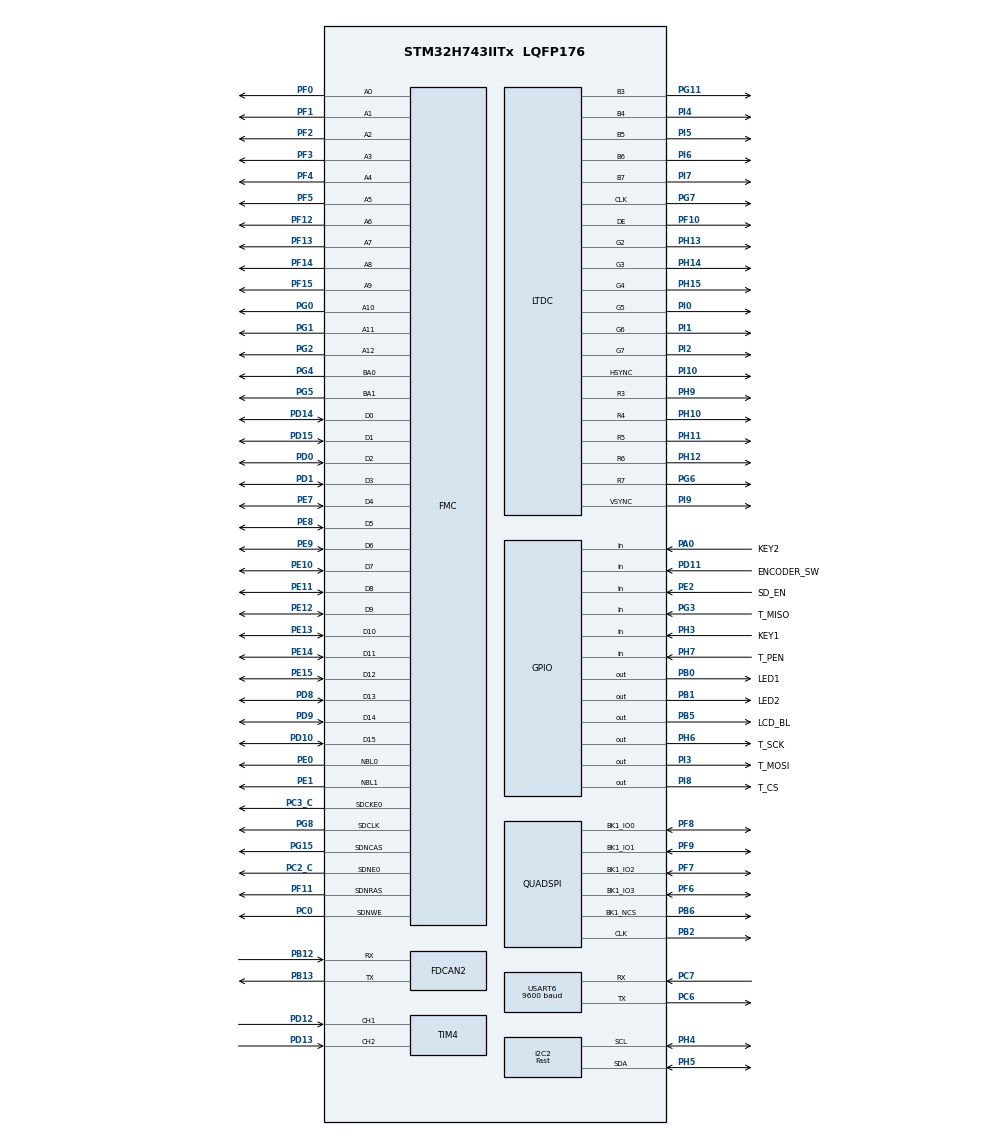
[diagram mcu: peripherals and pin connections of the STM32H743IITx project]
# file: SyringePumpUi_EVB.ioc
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CORTEX_M7.AccessPermission-Cortex_Memory_Protection_Unit_Region1_Settings=MPU_REGION_FULL_ACCESS
CORTEX_M7.AccessPermission-Cortex_Memory_Protection_Unit_Region2_Settings=MPU_REGION_FULL_ACCESS
CORTEX_M7.AccessPermission-Cortex_Memory_Protection_Unit_Region3_Settings=MPU_REGION_FULL_ACCESS
CORTEX_M7.AccessPermission-Cortex_Memory_Protection_Unit_Region4_Settings=MPU_REGION_FULL_ACCESS
CORTEX_M7.AccessPermission-Cortex_Memory_Protection_Unit_Region5_Settings=MPU_REGION_FULL_ACCESS
CORTEX_M7.AccessPermission-Cortex_Memory_Protection_Unit_Region6_Settings=MPU_REGION_FULL_ACCESS
CORTEX_M7.AccessPermission-Cortex_Memory_Protection_Unit_Region7_Settings=MPU_REGION_FULL_ACCESS
CORTEX_M7.BaseAddress-Cortex_Memory_Protection_Unit_Region1_Settings=0x90000000
CORTEX_M7.BaseAddress-Cortex_Memory_Protection_Unit_Region2_Settings=0xC0000000
CORTEX_M7.BaseAddress-Cortex_Memory_Protection_Unit_Region3_Settings=0x20000000
CORTEX_M7.BaseAddress-Cortex_Memory_Protection_Unit_Region4_Settings=0x24000000
CORTEX_M7.BaseAddress-Cortex_Memory_Protection_Unit_Region5_Settings=0x30000000
CORTEX_M7.BaseAddress-Cortex_Memory_Protection_Unit_Region6_Settings=0x38000000
CORTEX_M7.BaseAddress-Cortex_Memory_Protection_Unit_Region7_Settings=0x60000000
CORTEX_M7.CPU_DCache=Enabled
CORTEX_M7.CPU_ICache=Enabled
CORTEX_M7.DisableExec-Cortex_Memory_Protection_Unit_Region0_Settings=MPU_INSTRUCTION_ACCESS_DISABLE
CORTEX_M7.DisableExec-Cortex_Memory_Protection_Unit_Region2_Settings=MPU_INSTRUCTION_ACCESS_ENABLE
CORTEX_M7.Enable-Cortex_Memory_Protection_Unit_Region0_Settings=MPU_REGION_ENABLE
CORTEX_M7.Enable-Cortex_Memory_Protection_Unit_Region1_Settings=MPU_REGION_ENABLE
CORTEX_M7.Enable-Cortex_Memory_Protection_Unit_Region2_Settings=MPU_REGION_ENABLE
CORTEX_M7.Enable-Cortex_Memory_Protection_Unit_Region3_Settings=MPU_REGION_ENABLE
CORTEX_M7.Enable-Cortex_Memory_Protection_Unit_Region4_Settings=MPU_REGION_ENABLE
CORTEX_M7.Enable-Cortex_Memory_Protection_Unit_Region5_Settings=MPU_REGION_ENABLE
CORTEX_M7.Enable-Cortex_Memory_Protection_Unit_Region6_Settings=MPU_REGION_ENABLE
CORTEX_M7.Enable-Cortex_Memory_Protection_Unit_Region7_Settings=MPU_REGION_ENABLE
CORTEX_M7.Enable-Cortex_Memory_Protection_Unit_Region8_Settings=__NULL
CORTEX_M7.IsBufferable-Cortex_Memory_Protection_Unit_Region2_Settings=MPU_ACCESS_BUFFERABLE
CORTEX_M7.IsBufferable-Cortex_Memory_Protection_Unit_Region3_Settings=MPU_ACCESS_BUFFERABLE
CORTEX_M7.IsBufferable-Cortex_Memory_Protection_Unit_Region4_Settings=MPU_ACCESS_BUFFERABLE
CORTEX_M7.IsBufferable-Cortex_Memory_Protection_Unit_Region5_Settings=MPU_ACCESS_BUFFERABLE
CORTEX_M7.IsBufferable-Cortex_Memory_Protection_Unit_Region6_Settings=MPU_ACCESS_BUFFERABLE
CORTEX_M7.IsCacheable-Cortex_Memory_Protection_Unit_Region1_Settings=MPU_ACCESS_CACHEABLE
CORTEX_M7.IsCacheable-Cortex_Memory_Protection_Unit_Region2_Settings=MPU_ACCESS_CACHEABLE
CORTEX_M7.IsCacheable-Cortex_Memory_Protection_Unit_Region3_Settings=MPU_ACCESS_CACHEABLE
CORTEX_M7.IsCacheable-Cortex_Memory_Protection_Unit_Region4_Settings=MPU_ACCESS_CACHEABLE
CORTEX_M7.IsCacheable-Cortex_Memory_Protection_Unit_Region5_Settings=MPU_ACCESS_CACHEABLE
CORTEX_M7.IsCacheable-Cortex_Memory_Protection_Unit_Region6_Settings=MPU_ACCESS_CACHEABLE
CORTEX_M7.IsShareable-Cortex_Memory_Protection_Unit_Region0_Settings=MPU_ACCESS_SHAREABLE
CORTEX_M7.MPU_Control=__NULL
CORTEX_M7.Size-Cortex_Memory_Protection_Unit_Region0_Settings=MPU_REGION_SIZE_4GB
CORTEX_M7.Size-Cortex_Memory_Protection_Unit_Region1_Settings=MPU_REGION_SIZE_32MB
CORTEX_M7.Size-Cortex_Memory_Protection_Unit_Region2_Settings=MPU_REGION_SIZE_32MB
CORTEX_M7.Size-Cortex_Memory_Protection_Unit_Region3_Settings=MPU_REGION_SIZE_128KB
CORTEX_M7.Size-Cortex_Memory_Protection_Unit_Region4_Settings=MPU_REGION_SIZE_512KB
CORTEX_M7.Size-Cortex_Memory_Protection_Unit_Region5_Settings=MPU_REGION_SIZE_512KB
CORTEX_M7.Size-Cortex_Memory_Protection_Unit_Region6_Settings=MPU_REGION_SIZE_64KB
CORTEX_M7.Size-Cortex_Memory_Protection_Unit_Region7_Settings=MPU_REGION_SIZE_64KB
CORTEX_M7.SubRegionDisable-Cortex_Memory_Protection_Unit_Region0_Settings=0x87
DMA2D.ColorMode=DMA2D_OUTPUT_RGB565
Dma.I2C2_RX.0.Direction=DMA_PERIPH_TO_MEMORY
Dma.I2C2_RX.0.EventEnable=DISABLE
Dma.I2C2_RX.0.FIFOMode=DMA_FIFOMODE_DISABLE
Dma.I2C2_RX.0.Instance=DMA1_Stream0
Dma.I2C2_RX.0.MemDataAlignment=DMA_MDATAALIGN_BYTE
Dma.I2C2_RX.0.MemInc=DMA_MINC_ENABLE
Dma.I2C2_RX.0.Mode=DMA_NORMAL
Dma.I2C2_RX.0.PeriphDataAlignment=DMA_PDATAALIGN_BYTE
Dma.I2C2_RX.0.PeriphInc=DMA_PINC_DISABLE
Dma.I2C2_RX.0.Polarity=HAL_DMAMUX_REQ_GEN_RISING
Dma.I2C2_RX.0.Priority=DMA_PRIORITY_LOW
Dma.I2C2_RX.0.RequestNumber=1
Dma.I2C2_RX.0.SignalID=NONE
Dma.I2C2_RX.0.SyncEnable=DISABLE
Dma.I2C2_RX.0.SyncPolarity=HAL_DMAMUX_SYNC_NO_EVENT
Dma.I2C2_RX.0.SyncRequestNumber=1
Dma.I2C2_RX.0.SyncSignalID=NONE
Dma.I2C2_TX.1.Direction=DMA_MEMORY_TO_PERIPH
Dma.I2C2_TX.1.EventEnable=DISABLE
Dma.I2C2_TX.1.FIFOMode=DMA_FIFOMODE_DISABLE
Dma.I2C2_TX.1.Instance=DMA1_Stream1
Dma.I2C2_TX.1.MemDataAlignment=DMA_MDATAALIGN_BYTE
Dma.I2C2_TX.1.MemInc=DMA_MINC_ENABLE
Dma.I2C2_TX.1.Mode=DMA_NORMAL
Dma.I2C2_TX.1.PeriphDataAlignment=DMA_PDATAALIGN_BYTE
Dma.I2C2_TX.1.PeriphInc=DMA_PINC_DISABLE
Dma.I2C2_TX.1.Polarity=HAL_DMAMUX_REQ_GEN_RISING
Dma.I2C2_TX.1.Priority=DMA_PRIORITY_LOW
Dma.I2C2_TX.1.RequestNumber=1
Dma.I2C2_TX.1.SignalID=NONE
Dma.I2C2_TX.1.SyncEnable=DISABLE
Dma.I2C2_TX.1.SyncPolarity=HAL_DMAMUX_SYNC_NO_EVENT
Dma.I2C2_TX.1.SyncRequestNumber=1
Dma.I2C2_TX.1.SyncSignalID=NONE
Dma.Request0=I2C2_RX
Dma.Request1=I2C2_TX
FDCAN2.CalculateBaudRateNominal=1250000
FDCAN2.CalculateTimeBitNominal=800
FDCAN2.CalculateTimeQuantumNominal=160.0
FMC.CASLatency1=FMC_SDRAM_CAS_LATENCY_3
FMC.ColumnBitsNumber1=FMC_SDRAM_COLUMN_BITS_NUM_9
FMC.ExitSelfRefreshDelay1=8
FMC.LoadToActiveDelay1=2
FMC.RCDDelay1=2
FMC.RPDelay1=2
FMC.RPDelay2=2
FMC.ReadBurst1=FMC_SDRAM_RBURST_ENABLE
FMC.ReadBurst2=FMC_SDRAM_RBURST_ENABLE
FMC.ReadPipeDelay1=FMC_SDRAM_RPIPE_DELAY_0
FMC.RowCycleDelay1=7
FMC.RowCycleDelay2=7
FMC.SDClockPeriod1=FMC_SDRAM_CLOCK_PERIOD_2
FMC.SDClockPeriod2=FMC_SDRAM_CLOCK_PERIOD_2
FMC.SelfRefreshTime1=5
FMC.WriteRecoveryTime1=4
I2C2.CustomTiming=Disabled
I2C2.I2C_Fall_Time=300
I2C2.I2C_Rise_Time=300
I2C2.I2C_Speed_Mode=I2C_Fast
I2C2.Timing=0x10950C1E
LTDC.ActiveW=800
LTDC.Alpha_L0=255
LTDC.Alpha_L1=255
LTDC.DEPolarity=LTDC_DEPOLARITY_AH
LTDC.FBStartAdress_L0=0xc0000000
LTDC.Green_L0=0
LTDC.HBP=8
LTDC.HFP=8
LTDC.HSPolarity=LTDC_HSPOLARITY_AL
LTDC.HSync=1
LTDC.ImageHeight_L0=480
LTDC.ImageHeight_L1=480
LTDC.ImageWidth_L0=800
LTDC.Layers=0
LTDC.PCPolarity=LTDC_PCPOLARITY_IIPC
LTDC.PixelFormat_L0=LTDC_PIXEL_FORMAT_RGB565
LTDC.Red_L0=0
LTDC.VBP=8
LTDC.VFP=8
LTDC.VSPolarity=LTDC_VSPOLARITY_AL
LTDC.VSync=1
LTDC.WindowX0_L0=0
LTDC.WindowX1_L0=800
LTDC.WindowX1_L1=800
LTDC.WindowY0_L0=0
LTDC.WindowY1_L0=480
LTDC.WindowY1_L1=480
Mcu.Family=STM32H7
Mcu.Name=STM32H743IITx
Mcu.Package=LQFP176
NVIC.DMA1_Stream0_IRQn=true\:0\:0\:false\:false\:true\:false\:true\:true
NVIC.DMA1_Stream1_IRQn=true\:0\:0\:false\:false\:true\:false\:true\:true
NVIC.DMA2D_IRQn=true\:0\:0\:false\:false\:true\:true\:true\:true
NVIC.I2C2_ER_IRQn=true\:0\:0\:false\:false\:true\:true\:true\:true
NVIC.I2C2_EV_IRQn=true\:0\:0\:false\:false\:true\:true\:true\:true
NVIC.LTDC_ER_IRQn=true\:0\:0\:false\:false\:true\:true\:true\:true
NVIC.LTDC_IRQn=true\:0\:0\:false\:false\:true\:true\:true\:true
NVIC.PriorityGroup=NVIC_PRIORITYGROUP_4
NVIC.TIM4_IRQn=true\:0\:0\:false\:false\:true\:true\:true\:true
PA0.GPIO_Label=KEY2
PA0.GPIO_PuPd=GPIO_PULLUP
PA0.Signal=GPIO_Input
PA13\ (JTMS/SWDIO).Mode=Serial_Wire
PA13\ (JTMS/SWDIO).Signal=DEBUG_JTMS-SWDIO
PA14\ (JTCK/SWCLK).Mode=Serial_Wire
PA14\ (JTCK/SWCLK).Signal=DEBUG_JTCK-SWCLK
PB0.GPIO_Label=LED1
PB0.GPIO_Speed=GPIO_SPEED_FREQ_VERY_HIGH
PB0.PinState=GPIO_PIN_RESET
PB0.Signal=GPIO_Output
PB1.GPIO_Label=LED2
PB1.GPIO_Speed=GPIO_SPEED_FREQ_VERY_HIGH
PB1.Signal=GPIO_Output
PB12.GPIO_PuPd=GPIO_PULLUP
PB12.GPIO_Speed=GPIO_SPEED_FREQ_MEDIUM
PB12.Mode=FDCAN_Activate
PB12.Signal=FDCAN2_RX
PB13.Mode=FDCAN_Activate
PB13.Signal=FDCAN2_TX
PB2.GPIO_Speed=GPIO_SPEED_FREQ_VERY_HIGH
PB2.Mode=Single Bank 1
PB2.Signal=QUADSPI_CLK
PB5.GPIO_Label=LCD_BL
PB5.GPIO_Speed=GPIO_SPEED_FREQ_VERY_HIGH
PB5.PinState=GPIO_PIN_SET
PB5.Signal=GPIO_Output
PB6.GPIO_FM6=SYSCFG_PMCR_I2C_PB6_FMP
PB6.GPIO_Speed=GPIO_SPEED_FREQ_VERY_HIGH
PB6.Mode=Single Bank 1
PB6.Signal=QUADSPI_BK1_NCS
PC0.Signal=FMC_SDNWE
PC2_C.Mode=SdramChipSelect1_1
PC2_C.Signal=FMC_SDNE0
PC3_C.Mode=SdramChipSelect1_1
PC3_C.Signal=FMC_SDCKE0
PC6.Mode=Asynchronous
PC6.Signal=USART6_TX
PC7.Mode=Asynchronous
PC7.Signal=USART6_RX
PD0.Signal=FMC_D2_DA2
PD1.Signal=FMC_D3_DA3
PD10.Signal=FMC_D15_DA15
PD11.GPIO_Label=ENCODER_SW
PD11.GPIO_PuPd=GPIO_PULLUP
PD11.Signal=GPIO_Input
PD12.Signal=S_TIM4_CH1
PD13.Signal=S_TIM4_CH2
PD14.Signal=FMC_D0_DA0
PD15.Signal=FMC_D1_DA1
PD8.Signal=FMC_D13_DA13
PD9.Signal=FMC_D14_DA14
PE0.Signal=FMC_NBL0
PE1.Signal=FMC_NBL1
PE10.Signal=FMC_D7_DA7
PE11.Signal=FMC_D8_DA8
PE12.Signal=FMC_D9_DA9
PE13.Signal=FMC_D10_DA10
PE14.Signal=FMC_D11_DA11
PE15.Signal=FMC_D12_DA12
PE2.GPIO_Label=SD_EN
PE2.GPIO_PuPd=GPIO_PULLDOWN
PE2.Signal=GPIO_Input
PE7.Signal=FMC_D4_DA4
PE8.Signal=FMC_D5_DA5
PE9.Signal=FMC_D6_DA6
PF0.Signal=FMC_A0
PF1.Signal=FMC_A1
PF10.GPIO_Speed=GPIO_SPEED_FREQ_VERY_HIGH
PF10.Mode=RGB565
PF10.Signal=LTDC_DE
PF11.Signal=FMC_SDNRAS
PF12.Signal=FMC_A6
PF13.Signal=FMC_A7
PF14.Signal=FMC_A8
PF15.Signal=FMC_A9
PF2.Signal=FMC_A2
PF3.Signal=FMC_A3
PF4.Signal=FMC_A4
PF5.Signal=FMC_A5
PF6.GPIO_Speed=GPIO_SPEED_FREQ_VERY_HIGH
PF6.Mode=Single Bank 1
PF6.Signal=QUADSPI_BK1_IO3
PF7.GPIO_Speed=GPIO_SPEED_FREQ_VERY_HIGH
PF7.Mode=Single Bank 1
PF7.Signal=QUADSPI_BK1_IO2
PF8.GPIO_Speed=GPIO_SPEED_FREQ_VERY_HIGH
PF8.Mode=Single Bank 1
PF8.Signal=QUADSPI_BK1_IO0
PF9.GPIO_Speed=GPIO_SPEED_FREQ_VERY_HIGH
PF9.Mode=Single Bank 1
PF9.Signal=QUADSPI_BK1_IO1
PG0.Signal=FMC_A10
PG1.Signal=FMC_A11
PG11.GPIO_Speed=GPIO_SPEED_FREQ_VERY_HIGH
PG11.Mode=RGB565
PG11.Signal=LTDC_B3
PG15.Signal=FMC_SDNCAS
PG2.Signal=FMC_A12
PG3.GPIO_Label=T_MISO
PG3.GPIO_PuPd=GPIO_PULLUP
PG3.Signal=GPIO_Input
PG4.Signal=FMC_A14_BA0
PG5.Signal=FMC_A15_BA1
PG6.GPIO_Speed=GPIO_SPEED_FREQ_VERY_HIGH
PG6.Mode=RGB565
PG6.Signal=LTDC_R7
PG7.GPIO_Speed=GPIO_SPEED_FREQ_VERY_HIGH
PG7.Mode=RGB565
PG7.Signal=LTDC_CLK
PG8.Signal=FMC_SDCLK
PH0-OSC_IN\ (PH0).Mode=HSE-External-Oscillator
PH0-OSC_IN\ (PH0).Signal=RCC_OSC_IN
PH1-OSC_OUT\ (PH1).Mode=HSE-External-Oscillator
PH1-OSC_OUT\ (PH1).Signal=RCC_OSC_OUT
PH10.GPIO_Speed=GPIO_SPEED_FREQ_VERY_HIGH
PH10.Mode=RGB565
PH10.Signal=LTDC_R4
PH11.GPIO_Speed=GPIO_SPEED_FREQ_VERY_HIGH
PH11.Mode=RGB565
PH11.Signal=LTDC_R5
PH12.GPIO_Speed=GPIO_SPEED_FREQ_VERY_HIGH
PH12.Mode=RGB565
PH12.Signal=LTDC_R6
PH13.GPIO_Speed=GPIO_SPEED_FREQ_VERY_HIGH
PH13.Mode=RGB565
PH13.Signal=LTDC_G2
PH14.GPIO_Speed=GPIO_SPEED_FREQ_VERY_HIGH
PH14.Mode=RGB565
PH14.Signal=LTDC_G3
PH15.GPIO_Speed=GPIO_SPEED_FREQ_VERY_HIGH
PH15.Mode=RGB565
PH15.Signal=LTDC_G4
PH3.GPIO_Label=KEY1
PH3.GPIO_PuPd=GPIO_PULLUP
PH3.Signal=GPIO_Input
PH4.GPIO_Pu=GPIO_PULLUP
PH4.GPIO_Speed=GPIO_SPEED_FREQ_VERY_HIGH
PH4.Mode=I2C
PH4.Signal=I2C2_SCL
PH5.GPIO_Pu=GPIO_PULLUP
PH5.GPIO_Speed=GPIO_SPEED_FREQ_VERY_HIGH
PH5.Mode=I2C
PH5.Signal=I2C2_SDA
PH6.GPIO_Label=T_SCK
PH6.GPIO_PuPd=GPIO_PULLUP
PH6.GPIO_Speed=GPIO_SPEED_FREQ_VERY_HIGH
PH6.PinState=GPIO_PIN_SET
PH6.Signal=GPIO_Output
PH7.GPIO_Label=T_PEN
PH7.GPIO_PuPd=GPIO_PULLUP
PH7.Signal=GPIO_Input
PH9.GPIO_Speed=GPIO_SPEED_FREQ_VERY_HIGH
PH9.Mode=RGB565
PH9.Signal=LTDC_R3
PI0.GPIO_Speed=GPIO_SPEED_FREQ_VERY_HIGH
PI0.Mode=RGB565
PI0.Signal=LTDC_G5
PI1.GPIO_Speed=GPIO_SPEED_FREQ_VERY_HIGH
PI1.Mode=RGB565
PI1.Signal=LTDC_G6
PI10.GPIO_Speed=GPIO_SPEED_FREQ_VERY_HIGH
PI10.Mode=RGB565
PI10.Signal=LTDC_HSYNC
PI2.GPIO_Speed=GPIO_SPEED_FREQ_VERY_HIGH
PI2.Mode=RGB565
PI2.Signal=LTDC_G7
PI3.GPIO_Label=T_MOSI
PI3.GPIO_PuPd=GPIO_PULLUP
PI3.GPIO_Speed=GPIO_SPEED_FREQ_VERY_HIGH
PI3.PinState=GPIO_PIN_SET
PI3.Signal=GPIO_Output
PI4.GPIO_Speed=GPIO_SPEED_FREQ_VERY_HIGH
PI4.Mode=RGB565
PI4.Signal=LTDC_B4
PI5.GPIO_Speed=GPIO_SPEED_FREQ_VERY_HIGH
PI5.Mode=RGB565
PI5.Signal=LTDC_B5
PI6.GPIO_Speed=GPIO_SPEED_FREQ_VERY_HIGH
PI6.Mode=RGB565
PI6.Signal=LTDC_B6
PI7.GPIO_Speed=GPIO_SPEED_FREQ_VERY_HIGH
PI7.Mode=RGB565
PI7.Signal=LTDC_B7
PI8.GPIO_Label=T_CS
PI8.GPIO_PuPd=GPIO_PULLUP
PI8.PinState=GPIO_PIN_SET
PI8.Signal=GPIO_Output
PI9.GPIO_Speed=GPIO_SPEED_FREQ_VERY_HIGH
PI9.Mode=RGB565
PI9.Signal=LTDC_VSYNC
ProjectManager.HeapSize=0x1800
ProjectManager.StackSize=0x2000
ProjectManager.TargetToolchain=STM32CubeIDE
QUADSPI.ChipSelectHighTime=QSPI_CS_HIGH_TIME_1_CYCLE
QUADSPI.ClockMode=QSPI_CLOCK_MODE_3
QUADSPI.ClockPrescaler=4
QUADSPI.FifoThreshold=4
QUADSPI.FlashSize=24
QUADSPI.SampleShifting=QSPI_SAMPLE_SHIFTING_HALFCYCLE
RCC.ADCFreq_Value=133000000
RCC.APB1Freq_Value=50000000
RCC.APB2Freq_Value=100000000
RCC.APB3Freq_Value=100000000
RCC.APB4Freq_Value=100000000
RCC.CortexFreq_Value=400000000
RCC.D1PPRE=RCC_APB3_DIV2
RCC.D2PPRE1=RCC_APB1_DIV4
RCC.D2PPRE2=RCC_APB2_DIV2
RCC.D3PPRE=RCC_APB4_DIV2
RCC.DIVM1=5
RCC.DIVM2=25
RCC.DIVM3=1
RCC.DIVN1=160
RCC.DIVN2=266
RCC.DIVN3=6
RCC.DIVQ1=8
RCC.DIVR1=4
RCC.DIVR3=6
RCC.FMCCLockSelection=RCC_FMCCLKSOURCE_PLL2
RCC.HCLKFreq_Value=200000000
RCC.HPRE=RCC_HCLK_DIV2
RCC.PLL2FRACN=0
RCC.PLL3FRACN=0
RCC.PLLFRACN=0
RCC.PLLSourceVirtual=RCC_PLLSOURCE_HSE
RCC.QSPICLockSelection=RCC_QSPICLKSOURCE_PLL
RCC.RTCClockSelection=RCC_RTCCLKSOURCE_LSE
RCC.SYSCLKFreq_VALUE=400000000
RCC.SYSCLKSource=RCC_SYSCLKSOURCE_PLLCLK
RCC.USBFreq_Value=100000000
SH.FMC_A0.0=FMC_A0,13b-sda1
SH.FMC_A1.0=FMC_A1,13b-sda1
SH.FMC_A10.0=FMC_A10,13b-sda1
SH.FMC_A11.0=FMC_A11,13b-sda1
SH.FMC_A12.0=FMC_A12,13b-sda1
SH.FMC_A14_BA0.0=FMC_BA0,FourSdramBanks1
SH.FMC_A15_BA1.0=FMC_BA1,FourSdramBanks1
SH.FMC_A2.0=FMC_A2,13b-sda1
SH.FMC_A3.0=FMC_A3,13b-sda1
SH.FMC_A4.0=FMC_A4,13b-sda1
SH.FMC_A5.0=FMC_A5,13b-sda1
SH.FMC_A6.0=FMC_A6,13b-sda1
SH.FMC_A7.0=FMC_A7,13b-sda1
SH.FMC_A8.0=FMC_A8,13b-sda1
SH.FMC_A9.0=FMC_A9,13b-sda1
SH.FMC_D0_DA0.0=FMC_D0,sd-16b-d1
SH.FMC_D10_DA10.0=FMC_D10,sd-16b-d1
SH.FMC_D11_DA11.0=FMC_D11,sd-16b-d1
SH.FMC_D12_DA12.0=FMC_D12,sd-16b-d1
SH.FMC_D13_DA13.0=FMC_D13,sd-16b-d1
SH.FMC_D14_DA14.0=FMC_D14,sd-16b-d1
SH.FMC_D15_DA15.0=FMC_D15,sd-16b-d1
SH.FMC_D1_DA1.0=FMC_D1,sd-16b-d1
SH.FMC_D2_DA2.0=FMC_D2,sd-16b-d1
SH.FMC_D3_DA3.0=FMC_D3,sd-16b-d1
SH.FMC_D4_DA4.0=FMC_D4,sd-16b-d1
SH.FMC_D5_DA5.0=FMC_D5,sd-16b-d1
SH.FMC_D6_DA6.0=FMC_D6,sd-16b-d1
SH.FMC_D7_DA7.0=FMC_D7,sd-16b-d1
SH.FMC_D8_DA8.0=FMC_D8,sd-16b-d1
SH.FMC_D9_DA9.0=FMC_D9,sd-16b-d1
SH.FMC_NBL0.0=FMC_NBL0,Sd2ByteEnable1
SH.FMC_NBL1.0=FMC_NBL1,Sd2ByteEnable1
SH.FMC_SDCLK.0=FMC_SDCLK,13b-sda1
SH.FMC_SDNCAS.0=FMC_SDNCAS,13b-sda1
SH.FMC_SDNRAS.0=FMC_SDNRAS,13b-sda1
SH.FMC_SDNWE.0=FMC_SDNWE,13b-sda1
SH.S_TIM4_CH1.0=TIM4_CH1,Encoder_Interface
SH.S_TIM4_CH2.0=TIM4_CH2,Encoder_Interface
TIM4.IC1Polarity=TIM_ICPOLARITY_FALLING
USART6.BaudRate=9600
USART6.VirtualMode-Asynchronous=VM_ASYNC
VP_CRC_VS_CRC.Mode=CRC_Activate
VP_DMA2D_VS_DMA2D.Mode=DMA2D_Activate
board=custom

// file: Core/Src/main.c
/* USER CODE BEGIN Header */
/**
  ******************************************************************************
  * @file           : main.c
  * @brief          : Main program body
  ******************************************************************************
  * @attention
  *
  * Copyright (c) 2024 STMicroelectronics.
  * All rights reserved.
  *
  * This software is licensed under terms that can be found in the LICENSE file
  * in the root directory of this software component.
  * If no LICENSE file comes with this software, it is provided AS-IS.
  *
  ******************************************************************************
  */
/* USER CODE END Header */
#include "main.h"
#include "crc.h"
#include "dma.h"
#include "dma2d.h"
#include "fdcan.h"
#include "i2c.h"
#include "ltdc.h"
#include "quadspi.h"
#include "tim.h"
#include "usart.h"
#include "gpio.h"
#include "fmc.h"

/* USER CODE BEGIN Includes */
#include <stdio.h>
#include "lvgl/lvgl.h"
#include "lvgl_port_lcd.h"
#include "gui_guider.h"
#include "myInputDevice.h"
/* USER CODE END Includes */

/* USER CODE BEGIN PV */
lv_ui guider_ui;

/* USER CODE END PV */

void SystemClock_Config(void);

/* USER CODE BEGIN 0 */
#ifdef __GNUC__

#define PUTCHAR_PROTOTYPE int __io_putchar(int ch)

#else

#define PUTCHAR_PROTOTYPE int fputc(int ch, FILE *f)

#endif

PUTCHAR_PROTOTYPE

{

	HAL_UART_Transmit(&huart6, (uint8_t *)&ch, 1, HAL_MAX_DELAY);
	return ch;

}
/***********************************/

/* USER CODE END 0 */

int main(void)
{
/* Enable the CPU Cache */

  /* Enable I-Cache---------------------------------------------------------*/
  SCB_EnableICache();

  /* Enable D-Cache---------------------------------------------------------*/
  SCB_EnableDCache();

  /* MCU Configuration--------------------------------------------------------*/

  /* Reset of all peripherals, Initializes the Flash interface and the Systick. */
  HAL_Init();

  /* Configure the system clock */
  SystemClock_Config();

  /* Initialize all configured peripherals */
  MX_GPIO_Init();
  MX_DMA_Init();
  MX_FMC_Init();
  MX_LTDC_Init();
  MX_QUADSPI_Init();
  MX_CRC_Init();
  MX_I2C2_Init();
  MX_FDCAN2_Init();
  MX_DMA2D_Init();
  MX_USART6_UART_Init();
  MX_TIM4_Init();
  /* USER CODE BEGIN 2 */
  setvbuf(stdout, NULL, _IONBF, 0);
	HAL_GPIO_WritePin(LCD_BL_GPIO_Port, LCD_BL_Pin, GPIO_PIN_RESET);//enable Backlight

  lv_init();
  LCD_init();
  /* USER CODE END 2 */

  /* Infinite loop */
  /* USER CODE BEGIN WHILE */

  myIndrv();
  setup_ui(&guider_ui);
printf("hello world\n\r");

  while (1)
  {

    /* USER CODE END WHILE */

    /* USER CODE BEGIN 3 */
		HAL_Delay(1);
	  lv_task_handler();

  }
  /* USER CODE END 3 */
}

void SystemClock_Config(void)
{
  RCC_OscInitTypeDef RCC_OscInitStruct = {0};
  RCC_ClkInitTypeDef RCC_ClkInitStruct = {0};

  /** Supply configuration update enable
  */
  HAL_PWREx_ConfigSupply(PWR_LDO_SUPPLY);

  /** Configure the main internal regulator output voltage
  */
  __HAL_PWR_VOLTAGESCALING_CONFIG(PWR_REGULATOR_VOLTAGE_SCALE1);

  while(!__HAL_PWR_GET_FLAG(PWR_FLAG_VOSRDY)) {}

  /** Initializes the RCC Oscillators according to the specified parameters
  * in the RCC_OscInitTypeDef structure.
  */
  RCC_OscInitStruct.OscillatorType = RCC_OSCILLATORTYPE_HSE;
  RCC_OscInitStruct.HSEState = RCC_HSE_ON;
  RCC_OscInitStruct.PLL.PLLState = RCC_PLL_ON;
  RCC_OscInitStruct.PLL.PLLSource = RCC_PLLSOURCE_HSE;
  RCC_OscInitStruct.PLL.PLLM = 5;
  RCC_OscInitStruct.PLL.PLLN = 160;
  RCC_OscInitStruct.PLL.PLLP = 2;
  RCC_OscInitStruct.PLL.PLLQ = 8;
  RCC_OscInitStruct.PLL.PLLR = 4;
  RCC_OscInitStruct.PLL.PLLRGE = RCC_PLL1VCIRANGE_2;
  RCC_OscInitStruct.PLL.PLLVCOSEL = RCC_PLL1VCOWIDE;
  RCC_OscInitStruct.PLL.PLLFRACN = 0;
  if (HAL_RCC_OscConfig(&RCC_OscInitStruct) != HAL_OK)
  {
    Error_Handler();
  }

  /** Initializes the CPU, AHB and APB buses clocks
  */
  RCC_ClkInitStruct.ClockType = RCC_CLOCKTYPE_HCLK|RCC_CLOCKTYPE_SYSCLK
                              |RCC_CLOCKTYPE_PCLK1|RCC_CLOCKTYPE_PCLK2
                              |RCC_CLOCKTYPE_D3PCLK1|RCC_CLOCKTYPE_D1PCLK1;
  RCC_ClkInitStruct.SYSCLKSource = RCC_SYSCLKSOURCE_PLLCLK;
  RCC_ClkInitStruct.SYSCLKDivider = RCC_SYSCLK_DIV1;
  RCC_ClkInitStruct.AHBCLKDivider = RCC_HCLK_DIV2;
  RCC_ClkInitStruct.APB3CLKDivider = RCC_APB3_DIV2;
  RCC_ClkInitStruct.APB1CLKDivider = RCC_APB1_DIV4;
  RCC_ClkInitStruct.APB2CLKDivider = RCC_APB2_DIV2;
  RCC_ClkInitStruct.APB4CLKDivider = RCC_APB4_DIV2;

  if (HAL_RCC_ClockConfig(&RCC_ClkInitStruct, FLASH_LATENCY_2) != HAL_OK)
  {
    Error_Handler();
  }
}

void Error_Handler(void)
{
  __disable_irq();
  while (1)
  {
  }
}
